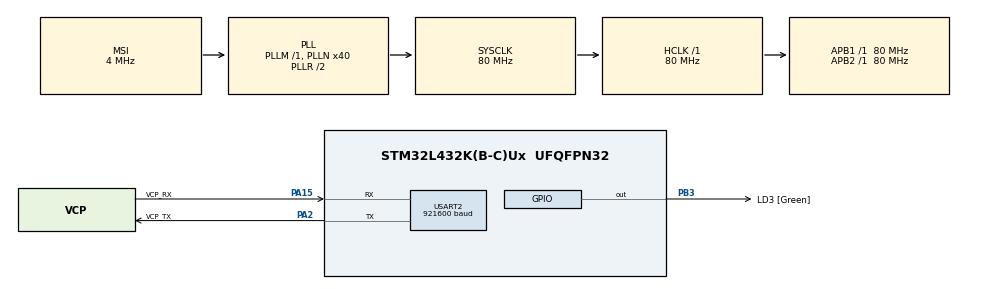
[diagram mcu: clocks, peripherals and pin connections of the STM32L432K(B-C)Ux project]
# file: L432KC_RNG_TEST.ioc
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Mcu.Family=STM32L4
Mcu.Name=STM32L432K(B-C)Ux
Mcu.Package=UFQFPN32
NVIC.PriorityGroup=NVIC_PRIORITYGROUP_4
NVIC.RCC_IRQn=true\:0\:0\:false\:false\:true\:true
NVIC.TIM6_DAC_IRQn=true\:0\:0\:false\:false\:true\:true
PA0.GPIO_Label=MCO [High speed clock in]
PA0.Mode=HSE-External-Clock-Source-for-LittleOrca
PA0.Signal=RCC_CK_IN
PA13\ (JTMS-SWDIO).GPIO_Label=SWDIO
PA13\ (JTMS-SWDIO).Mode=Serial_Wire
PA13\ (JTMS-SWDIO).Signal=SYS_JTMS-SWDIO
PA14\ (JTCK-SWCLK).GPIO_Label=SWCLK
PA14\ (JTCK-SWCLK).Mode=Serial_Wire
PA14\ (JTCK-SWCLK).Signal=SYS_JTCK-SWCLK
PA15\ (JTDI).GPIO_Label=VCP_RX
PA15\ (JTDI).Mode=Asynchronous
PA15\ (JTDI).Signal=USART2_RX
PA2.GPIO_Label=VCP_TX
PA2.Mode=Asynchronous
PA2.Signal=USART2_TX
PB3\ (JTDO-TRACESWO).GPIO_Label=LD3 [Green]
PB3\ (JTDO-TRACESWO).Signal=GPIO_Output
PC14-OSC32_IN\ (PC14).Mode=LSE-External-Oscillator
PC14-OSC32_IN\ (PC14).Signal=RCC_OSC32_IN
PC15-OSC32_OUT\ (PC15).Mode=LSE-External-Oscillator
PC15-OSC32_OUT\ (PC15).Signal=RCC_OSC32_OUT
ProjectManager.HeapSize=0x200
ProjectManager.StackSize=0x400
ProjectManager.TargetToolchain=TrueSTUDIO
RCC.ADCFreq_Value=32000000
RCC.AHBFreq_Value=80000000
RCC.APB1Freq_Value=80000000
RCC.APB1TimFreq_Value=80000000
RCC.APB2Freq_Value=80000000
RCC.APB2TimFreq_Value=80000000
RCC.CortexFreq_Value=80000000
RCC.HCLKFreq_Value=80000000
RCC.HSE_VALUE=8000000
RCC.HSI16_VALUE=16000000
RCC.HSI48_VALUE=48000000
RCC.HSI_VALUE=16000000
RCC.MSI_VALUE=4000000
RCC.PLLMUL=RCC_PLLMUL_4
RCC.PLLN=40
RCC.PLLSAI1N=16
RCC.SYSCLKFreq_VALUE=80000000
RCC.SYSCLKSource=RCC_SYSCLKSOURCE_PLLCLK
RCC.USBFreq_Value=32000000
RCC.VCOOutputFreq_Value=160000000
TIM6.AutoReloadPreload=TIM_AUTORELOAD_PRELOAD_DISABLE
TIM6.Period=4999
TIM6.Prescaler=7999
USART2.BaudRate=921600
USART2.VirtualMode-Asynchronous=VM_ASYNC
VP_RNG_VS_RNG.Mode=RNG_Activate
VP_TIM6_VS_ClockSourceINT.Mode=Enable_Timer
board=NUCLEO-L432KC

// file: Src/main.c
/**
  ******************************************************************************
  * @file           : main.c
  * @brief          : Main program body
  ******************************************************************************
  ** This notice applies to any and all portions of this file
  * that are not between comment pairs USER CODE BEGIN and
  * USER CODE END. Other portions of this file, whether
  * inserted by the user or by software development tools
  * are owned by their respective copyright owners.
  *
  * COPYRIGHT(c) 2018 STMicroelectronics
  *
  * Redistribution and use in source and binary forms, with or without modification,
  * are permitted provided that the following conditions are met:
  *   1. Redistributions of source code must retain the above copyright notice,
  *      this list of conditions and the following disclaimer.
  *   2. Redistributions in binary form must reproduce the above copyright notice,
  *      this list of conditions and the following disclaimer in the documentation
  *      and/or other materials provided with the distribution.
  *   3. Neither the name of STMicroelectronics nor the names of its contributors
  *      may be used to endorse or promote products derived from this software
  *      without specific prior written permission.
  *
  * THIS SOFTWARE IS PROVIDED BY THE COPYRIGHT HOLDERS AND CONTRIBUTORS "AS IS"
  * AND ANY EXPRESS OR IMPLIED WARRANTIES, INCLUDING, BUT NOT LIMITED TO, THE
  * IMPLIED WARRANTIES OF MERCHANTABILITY AND FITNESS FOR A PARTICULAR PURPOSE ARE
  * DISCLAIMED. IN NO EVENT SHALL THE COPYRIGHT HOLDER OR CONTRIBUTORS BE LIABLE
  * FOR ANY DIRECT, INDIRECT, INCIDENTAL, SPECIAL, EXEMPLARY, OR CONSEQUENTIAL
  * DAMAGES (INCLUDING, BUT NOT LIMITED TO, PROCUREMENT OF SUBSTITUTE GOODS OR
  * SERVICES; LOSS OF USE, DATA, OR PROFITS; OR BUSINESS INTERRUPTION) HOWEVER
  * CAUSED AND ON ANY THEORY OF LIABILITY, WHETHER IN CONTRACT, STRICT LIABILITY,
  * OR TORT (INCLUDING NEGLIGENCE OR OTHERWISE) ARISING IN ANY WAY OUT OF THE USE
  * OF THIS SOFTWARE, EVEN IF ADVISED OF THE POSSIBILITY OF SUCH DAMAGE.
  *
  ******************************************************************************
  */
#include "main.h"
#include "stm32l4xx_hal.h"

/* USER CODE BEGIN Includes */
#include <stdio.h>
#include <string.h>
#include "arm_math.h"
/* USER CODE END Includes */

RNG_HandleTypeDef hrng;
TIM_HandleTypeDef htim6;
UART_HandleTypeDef huart2;

/* USER CODE BEGIN PV */
/* Private variables ---------------------------------------------------------*/

#define FLASH_USER_START_ADDR   ADDR_FLASH_PAGE_127   /* Start @ of user Flash area */
#define FLASH_USER_END_ADDR     ADDR_FLASH_PAGE_127 + FLASH_PAGE_SIZE - 1   /* End @ of user Flash area */

#define USER_DATA1				(ADDR_FLASH_PAGE_127)
#define USER_DATA2				(ADDR_FLASH_PAGE_127+   8)
#define USER_DATA3				(ADDR_FLASH_PAGE_127+  16)
#define USER_DATA4				(ADDR_FLASH_PAGE_127+  24)

#define DATA_64                 ((uint64_t)0x1234567812345678)
#define DATA_32                 ((uint32_t)0xABCDEF12)

FLASH_EraseInitTypeDef EraseStruct,EraseInitStruct;

volatile uint32_t TicCount = 0;
uint32_t rnd,count=0;
volatile uint32_t nCnt=0,Rst=0;

uint32_t FirstPage = 0, NbOfPages = 0, BankNumber = 0;
uint32_t Address = 0, PAGEError = 0;
__IO uint32_t data32 = 0 , MemoryProgramStatus = 0;

/* USER CODE END PV */

void SystemClock_Config(void);
static void MX_GPIO_Init(void);
static void MX_USART2_UART_Init(void);
static void MX_RNG_Init(void);
static void MX_TIM6_Init(void);

static uint32_t GetPage(uint32_t Address);
static uint32_t GetBank(uint32_t Address);

static uint32_t GetPage(uint32_t Addr)
{
  uint32_t page = 0;

  if (Addr < (FLASH_BASE + FLASH_BANK_SIZE))
  {
    /* Bank 1 */
    page = (Addr - FLASH_BASE) / FLASH_PAGE_SIZE;
  }
  else
  {
    /* Bank 2 */
    page = (Addr - (FLASH_BASE + FLASH_BANK_SIZE)) / FLASH_PAGE_SIZE;
  }

  return page;
}

static uint32_t GetBank(uint32_t Addr)
{
  return FLASH_BANK_1;
}

/* USER CODE BEGIN PFP */
/* Private function prototypes -----------------------------------------------*/
void HAL_TIM_PeriodElapsedCallback(TIM_HandleTypeDef *htim);
/* USER CODE END PFP */

/* USER CODE BEGIN 0 */
#ifdef __GNUC__
int _write(int file,uint8_t*ptr,int len)
{
	HAL_UART_Transmit(&huart2,ptr,len,1000);
return len;
}
#elif (__ICCARM__||__CC_ARM)
int fputc(int c,FILE*stream)
{
	HAL_UART_Transmit(&huart2,(uint8_t*)&c,1,1000);
	return c;
}
#endif

void HAL_TIM_PeriodElapsedCallback(TIM_HandleTypeDef *htim)
{
	if(htim->Instance==TIM6)		Rst=1;
}

/* USER CODE END 0 */

int main(void)
{

  /* MCU Configuration----------------------------------------------------------*/

  /* Reset of all peripherals, Initializes the Flash interface and the Systick. */
  HAL_Init();

  /* Configure the system clock */
  SystemClock_Config();

  /* Initialize all configured peripherals */
  MX_GPIO_Init();
  MX_USART2_UART_Init();
  MX_RNG_Init();
  MX_TIM6_Init();
  /* USER CODE BEGIN 2 */

  while(HAL_TIM_Base_Start_IT(&htim6)!=HAL_OK);

  /* USER CODE END 2 */

  /* Infinite loop */
  /* USER CODE BEGIN WHILE */
  volatile double d1,d2;
  volatile int    er=0;

  HAL_FLASH_Unlock();
  __HAL_FLASH_CLEAR_FLAG(FLASH_FLAG_OPTVERR);

  FirstPage = GetPage(FLASH_USER_START_ADDR);
  NbOfPages = GetPage(FLASH_USER_END_ADDR) - FirstPage + 1;
  BankNumber = GetBank(FLASH_USER_START_ADDR);

  // Fill EraseInit structure
  EraseInitStruct.TypeErase   = FLASH_TYPEERASE_PAGES;
  EraseInitStruct.Banks       = BankNumber;             // 1 bank
  EraseInitStruct.Page        = FirstPage;              // 127 page
  EraseInitStruct.NbPages     = NbOfPages;              // 1 page

  while(HAL_FLASHEx_Erase(&EraseInitStruct, &PAGEError) != HAL_OK);

  if (HAL_FLASH_Program(FLASH_TYPEPROGRAM_DOUBLEWORD, USER_DATA1, 0x1967) != HAL_OK);
  if (HAL_FLASH_Program(FLASH_TYPEPROGRAM_DOUBLEWORD, USER_DATA2, BankNumber) != HAL_OK);
  if (HAL_FLASH_Program(FLASH_TYPEPROGRAM_DOUBLEWORD, USER_DATA3, FirstPage) != HAL_OK);
  if (HAL_FLASH_Program(FLASH_TYPEPROGRAM_DOUBLEWORD, USER_DATA4, NbOfPages) != HAL_OK);

  HAL_FLASH_Lock();

 /*
  Address = FLASH_USER_START_ADDR;

   while (Address < FLASH_USER_END_ADDR)
   {
     if (HAL_FLASH_Program(FLASH_TYPEPROGRAM_DOUBLEWORD, USER_DATA1, DATA_32) == HAL_OK)
     {
       Address = Address + 8;
     }
    else
     {
       while (1)
       {
         HAL_Delay(2000);
       }
     }
   } */

  while (1)
  {
	  rnd = HAL_RNG_GetRandomNumber(&hrng);
  /* USER CODE END WHILE */

  /* USER CODE BEGIN 3 */

	  d1 = arm_sin_f32(nCnt*3.141592/180);
	  d2 = sin(nCnt*3.141592/180);
	  /*
	  if(Rst)
	  {
		// HAL_GPIO_TogglePin(LD3_GPIO_Port, LD3_Pin);
		printf("Null Count : %lu\r\n",nCnt);
		nCnt = 0;
		Rst=0;
	  } */
	  er += (int)((d1-d2)*10000);
//    printf("%5lu%15.10f%15.10f%5d\r\n",nCnt,d1,d2,er);

	  printf("%lx : %lx\r\n",USER_DATA1,*(__IO uint64_t *)USER_DATA1);
	  printf("%lx : %lx\r\n",USER_DATA2,*(__IO uint64_t *)USER_DATA2);
	  printf("%x : %x\r\n",USER_DATA3,*(__IO uint64_t *)USER_DATA3);
	  printf("%x : %x\r\n",USER_DATA4,*(__IO uint64_t *)USER_DATA4);
	  nCnt++;
	  // FlashMemoryRead();
	  HAL_Delay(1000);

  }
  /* USER CODE END 3 */

}

void SystemClock_Config(void)
{

  RCC_OscInitTypeDef RCC_OscInitStruct;
  RCC_ClkInitTypeDef RCC_ClkInitStruct;
  RCC_PeriphCLKInitTypeDef PeriphClkInit;

    /**Configure LSE Drive Capability
    */
  HAL_PWR_EnableBkUpAccess();

  __HAL_RCC_LSEDRIVE_CONFIG(RCC_LSEDRIVE_LOW);

    /**Initializes the CPU, AHB and APB busses clocks
    */
  RCC_OscInitStruct.OscillatorType = RCC_OSCILLATORTYPE_LSE|RCC_OSCILLATORTYPE_MSI;
  RCC_OscInitStruct.LSEState = RCC_LSE_ON;
  RCC_OscInitStruct.MSIState = RCC_MSI_ON;
  RCC_OscInitStruct.MSICalibrationValue = 0;
  RCC_OscInitStruct.MSIClockRange = RCC_MSIRANGE_6;
  RCC_OscInitStruct.PLL.PLLState = RCC_PLL_ON;
  RCC_OscInitStruct.PLL.PLLSource = RCC_PLLSOURCE_MSI;
  RCC_OscInitStruct.PLL.PLLM = 1;
  RCC_OscInitStruct.PLL.PLLN = 40;
  RCC_OscInitStruct.PLL.PLLP = RCC_PLLP_DIV7;
  RCC_OscInitStruct.PLL.PLLQ = RCC_PLLQ_DIV2;
  RCC_OscInitStruct.PLL.PLLR = RCC_PLLR_DIV2;
  if (HAL_RCC_OscConfig(&RCC_OscInitStruct) != HAL_OK)
  {
    _Error_Handler(__FILE__, __LINE__);
  }

    /**Initializes the CPU, AHB and APB busses clocks
    */
  RCC_ClkInitStruct.ClockType = RCC_CLOCKTYPE_HCLK|RCC_CLOCKTYPE_SYSCLK
                              |RCC_CLOCKTYPE_PCLK1|RCC_CLOCKTYPE_PCLK2;
  RCC_ClkInitStruct.SYSCLKSource = RCC_SYSCLKSOURCE_PLLCLK;
  RCC_ClkInitStruct.AHBCLKDivider = RCC_SYSCLK_DIV1;
  RCC_ClkInitStruct.APB1CLKDivider = RCC_HCLK_DIV1;
  RCC_ClkInitStruct.APB2CLKDivider = RCC_HCLK_DIV1;

  if (HAL_RCC_ClockConfig(&RCC_ClkInitStruct, FLASH_LATENCY_4) != HAL_OK)
  {
    _Error_Handler(__FILE__, __LINE__);
  }

  PeriphClkInit.PeriphClockSelection = RCC_PERIPHCLK_USART2|RCC_PERIPHCLK_RNG;
  PeriphClkInit.Usart2ClockSelection = RCC_USART2CLKSOURCE_PCLK1;
  PeriphClkInit.RngClockSelection = RCC_RNGCLKSOURCE_PLLSAI1;
  PeriphClkInit.PLLSAI1.PLLSAI1Source = RCC_PLLSOURCE_MSI;
  PeriphClkInit.PLLSAI1.PLLSAI1M = 1;
  PeriphClkInit.PLLSAI1.PLLSAI1N = 16;
  PeriphClkInit.PLLSAI1.PLLSAI1P = RCC_PLLP_DIV7;
  PeriphClkInit.PLLSAI1.PLLSAI1Q = RCC_PLLQ_DIV2;
  PeriphClkInit.PLLSAI1.PLLSAI1R = RCC_PLLR_DIV2;
  PeriphClkInit.PLLSAI1.PLLSAI1ClockOut = RCC_PLLSAI1_48M2CLK;
  if (HAL_RCCEx_PeriphCLKConfig(&PeriphClkInit) != HAL_OK)
  {
    _Error_Handler(__FILE__, __LINE__);
  }

    /**Configure the main internal regulator output voltage
    */
  if (HAL_PWREx_ControlVoltageScaling(PWR_REGULATOR_VOLTAGE_SCALE1) != HAL_OK)
  {
    _Error_Handler(__FILE__, __LINE__);
  }

    /**Configure the Systick interrupt time
    */
  HAL_SYSTICK_Config(HAL_RCC_GetHCLKFreq()/1000);

    /**Configure the Systick
    */
  HAL_SYSTICK_CLKSourceConfig(SYSTICK_CLKSOURCE_HCLK);

    /**Enable MSI Auto calibration
    */
  HAL_RCCEx_EnableMSIPLLMode();

  /* SysTick_IRQn interrupt configuration */
  HAL_NVIC_SetPriority(SysTick_IRQn, 0, 0);
}

/* RNG init function */
static void MX_RNG_Init(void)
{

  hrng.Instance = RNG;
  if (HAL_RNG_Init(&hrng) != HAL_OK)
  {
    _Error_Handler(__FILE__, __LINE__);
  }

}

/* TIM6 init function */
static void MX_TIM6_Init(void)
{

  TIM_MasterConfigTypeDef sMasterConfig;

  htim6.Instance = TIM6;
  htim6.Init.Prescaler = 7999;
  htim6.Init.CounterMode = TIM_COUNTERMODE_UP;
  htim6.Init.Period = 4999;
  htim6.Init.AutoReloadPreload = TIM_AUTORELOAD_PRELOAD_DISABLE;
  if (HAL_TIM_Base_Init(&htim6) != HAL_OK)
  {
    _Error_Handler(__FILE__, __LINE__);
  }

  sMasterConfig.MasterOutputTrigger = TIM_TRGO_RESET;
  sMasterConfig.MasterSlaveMode = TIM_MASTERSLAVEMODE_DISABLE;
  if (HAL_TIMEx_MasterConfigSynchronization(&htim6, &sMasterConfig) != HAL_OK)
  {
    _Error_Handler(__FILE__, __LINE__);
  }

}

/* USART2 init function */
static void MX_USART2_UART_Init(void)
{

  huart2.Instance = USART2;
  huart2.Init.BaudRate = 115200;
  huart2.Init.WordLength = UART_WORDLENGTH_8B;
  huart2.Init.StopBits = UART_STOPBITS_1;
  huart2.Init.Parity = UART_PARITY_NONE;
  huart2.Init.Mode = UART_MODE_TX_RX;
  huart2.Init.HwFlowCtl = UART_HWCONTROL_NONE;
  huart2.Init.OverSampling = UART_OVERSAMPLING_16;
  huart2.Init.OneBitSampling = UART_ONE_BIT_SAMPLE_DISABLE;
  huart2.AdvancedInit.AdvFeatureInit = UART_ADVFEATURE_NO_INIT;
  if (HAL_UART_Init(&huart2) != HAL_OK)
  {
    _Error_Handler(__FILE__, __LINE__);
  }

}

/** Configure pins as
        * Analog
        * Input
        * Output
        * EVENT_OUT
        * EXTI
*/
static void MX_GPIO_Init(void)
{

  GPIO_InitTypeDef GPIO_InitStruct;

  /* GPIO Ports Clock Enable */
  __HAL_RCC_GPIOC_CLK_ENABLE();
  __HAL_RCC_GPIOA_CLK_ENABLE();
  __HAL_RCC_GPIOB_CLK_ENABLE();

  /*Configure GPIO pin Output Level */
  HAL_GPIO_WritePin(LD3_GPIO_Port, LD3_Pin, GPIO_PIN_RESET);

  /*Configure GPIO pin : LD3_Pin */
  GPIO_InitStruct.Pin = LD3_Pin;
  GPIO_InitStruct.Mode = GPIO_MODE_OUTPUT_PP;
  GPIO_InitStruct.Pull = GPIO_NOPULL;
  GPIO_InitStruct.Speed = GPIO_SPEED_FREQ_LOW;
  HAL_GPIO_Init(LD3_GPIO_Port, &GPIO_InitStruct);

}

void _Error_Handler(char *file, int line)
{
  while(1)
  {
  }
}

/************************ (C) COPYRIGHT STMicroelectronics *****END OF FILE****/
